CM_ "IMPORT _bosch_2018.dbc"

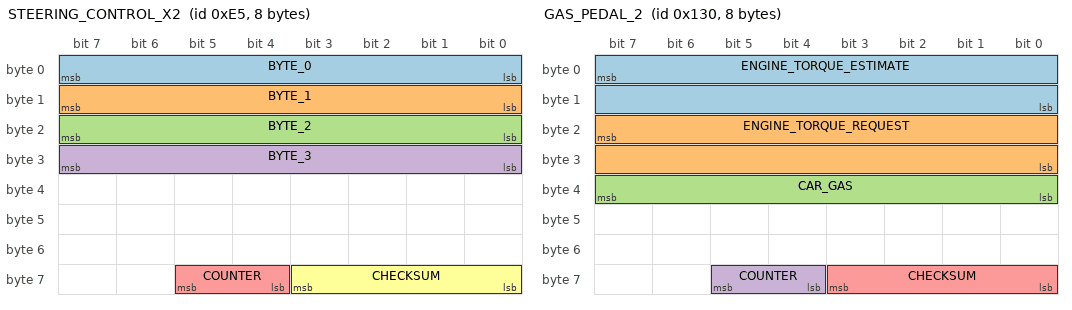
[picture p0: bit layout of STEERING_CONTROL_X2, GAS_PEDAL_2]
BO_ 229 STEERING_CONTROL_X2: 8 XXX
 SG_ BYTE_0 : 0|8@1+ (1,0) [0|255] "" XXX
 SG_ BYTE_1 : 8|8@1+ (1,0) [0|255] "" XXX
 SG_ BYTE_2 : 16|8@1+ (1,0) [0|255] "" XXX
 SG_ BYTE_3 : 24|8@1+ (1,0) [0|255] "" XXX
 SG_ COUNTER : 61|2@0+ (1,0) [0|3] "" XXX
 SG_ CHECKSUM : 59|4@0+ (1,0) [0|15] "" XXX

BO_ 304 GAS_PEDAL_2: 8 PCM
 SG_ ENGINE_TORQUE_ESTIMATE : 7|16@0- (1,0) [-1000|1000] "Nm" EON
 SG_ ENGINE_TORQUE_REQUEST : 23|16@0- (1,0) [-1000|1000] "Nm" EON
 SG_ CAR_GAS : 39|8@0+ (1,0) [0|255] "" EON
 SG_ COUNTER : 61|2@0+ (1,0) [0|3] "" EON
 SG_ CHECKSUM : 59|4@0+ (1,0) [0|15] "" EON

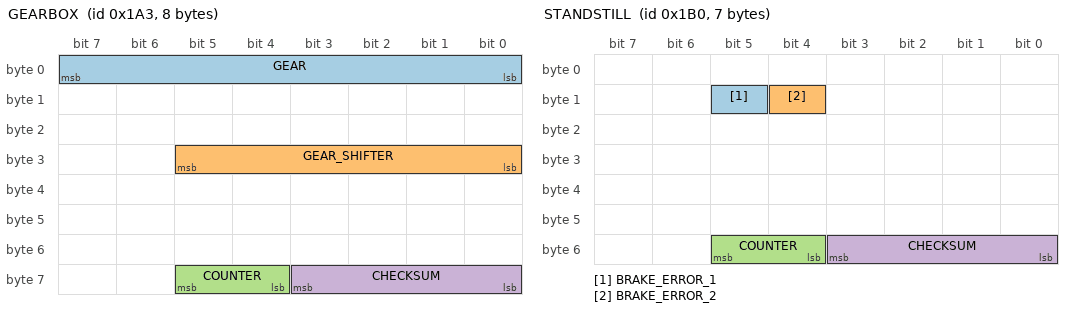
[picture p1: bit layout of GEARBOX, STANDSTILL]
BO_ 419 GEARBOX: 8 PCM
 SG_ GEAR : 7|8@0+ (1,0) [0|255] "" EON
 SG_ GEAR_SHIFTER : 29|6@0+ (1,0) [0|63] "" EON
 SG_ COUNTER : 61|2@0+ (1,0) [0|3] "" EON
 SG_ CHECKSUM : 59|4@0+ (1,0) [0|3] "" EON

BO_ 432 STANDSTILL: 7 VSA
 SG_ BRAKE_ERROR_1 : 13|1@0+ (1,0) [0|1] "" EON
 SG_ BRAKE_ERROR_2 : 12|1@0+ (1,0) [0|1] "" EON
 SG_ COUNTER : 53|2@0+ (1,0) [0|3] "" EON
 SG_ CHECKSUM : 51|4@0+ (1,0) [0|15] "" EON

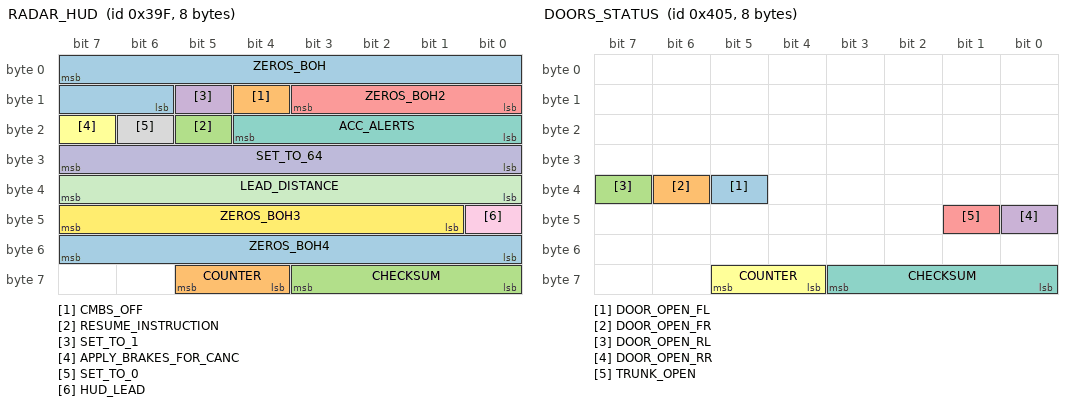
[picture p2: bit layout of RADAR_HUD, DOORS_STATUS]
BO_ 927 RADAR_HUD: 8 RADAR
 SG_ ZEROS_BOH : 7|10@0+ (1,0) [0|127] "" BDY
 SG_ CMBS_OFF : 12|1@0+ (1,0) [0|1] "" BDY
 SG_ RESUME_INSTRUCTION : 21|1@0+ (1,0) [0|1] "" XXX
 SG_ SET_TO_1 : 13|1@0+ (1,0) [0|1] "" BDY
 SG_ ZEROS_BOH2 : 11|4@0+ (1,0) [0|1] "" XXX
 SG_ APPLY_BRAKES_FOR_CANC : 23|1@0+ (1,0) [0|1] "" XXX
 SG_ ACC_ALERTS : 20|5@0+ (1,0) [0|1] "" BDY
 SG_ SET_TO_0 : 22|1@0+ (1,0) [0|1] "" XXX
 SG_ HUD_LEAD : 40|1@0+ (1,0) [0|1] "" XXX
 SG_ SET_TO_64 : 31|8@0+ (1,0) [0|255] "" XXX
 SG_ LEAD_DISTANCE : 39|8@0+ (1,0) [0|255] "" XXX
 SG_ ZEROS_BOH3 : 47|7@0+ (1,0) [0|127] "" XXX
 SG_ ZEROS_BOH4 : 55|8@0+ (1,0) [0|255] "" XXX
 SG_ COUNTER : 61|2@0+ (1,0) [0|3] "" XXX
 SG_ CHECKSUM : 59|4@0+ (1,0) [0|15] "" XXX

BO_ 1029 DOORS_STATUS: 8 BDY
 SG_ DOOR_OPEN_FL : 37|1@0+ (1,0) [0|1] "" EON
 SG_ DOOR_OPEN_FR : 38|1@0+ (1,0) [0|1] "" EON
 SG_ DOOR_OPEN_RL : 39|1@0+ (1,0) [0|1] "" EON
 SG_ DOOR_OPEN_RR : 40|1@0+ (1,0) [0|1] "" EON
 SG_ TRUNK_OPEN : 41|1@0+ (1,0) [0|1] "" EON
 SG_ COUNTER : 61|2@0+ (1,0) [0|3] "" EON
 SG_ CHECKSUM : 59|4@0+ (1,0) [0|15] "" EON

 VAL_ 419 GEAR  10 "R" 1 "D" 0 "P";
 VAL_ 419 GEAR_SHIFTER  32 "D" 16 "N" 8 "R" 4 "P" ;

CM_ "CHFFR_METRIC 330 STEER_ANGLE STEER_ANGLE 0.36 180; CHFFR_METRIC 380 ENGINE_RPM ENGINE_RPM 1 0; CHFFR_METRIC 804 ENGINE_TEMPERATURE ENGINE_TEMPERATURE 1 0";
